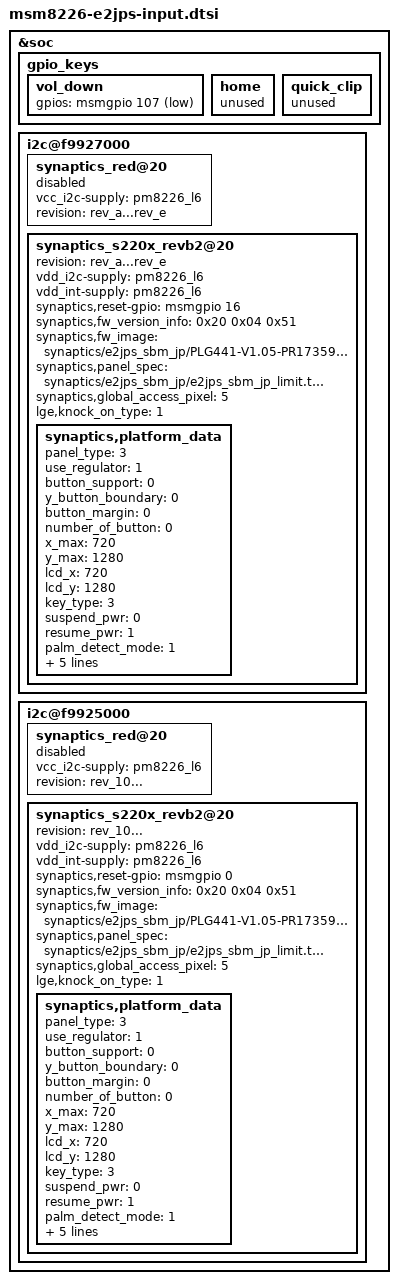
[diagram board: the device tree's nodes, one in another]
/* Copyright (c) 2013, LGE Electronics. All rights reserved.
 *
 * This program is free software; you can redistribute it and/or modify
 * it under the terms of the GNU General Public License version 2 and
 * only version 2 as published by the Free Software Foundation.
 *
 * This program is distributed in the hope that it will be useful,
 * but WITHOUT ANY WARRANTY; without even the implied warranty of
 * MERCHANTABILITY or FITNESS FOR A PARTICULAR PURPOSE.  See the
 * GNU General Public License for more details.
 */

&soc {
	gpio_keys {
		
		vol_down {
			gpios = <&msmgpio 107 0x1>;
		};
		
		home {
			unused;
		};

		quick_clip {
			unused;
		};
	};

	i2c@f9927000 { /* BLSP1 QUP5 */
		
		synaptics_red@20 {
			status = "disable";
			vcc_i2c-supply = <&pm8226_l6>;
			revision = "rev_a...rev_e";
		};
		
		synaptics_s220x_revb2@20 {
			status = "ok";
			revision = "rev_a...rev_e";
			vdd_i2c-supply = <&pm8226_l6>;
			vdd_int-supply = <&pm8226_l6>;
			synaptics,reset-gpio = <&msmgpio 16 0x00>;
			synaptics,fw_version_info = <0x20 0x04 0x51>;
			synaptics,fw_image = "synaptics/e2jps_sbm_jp/PLG441-V1.05-PR1735936-DS4.3.5.1.16_20045185.img";
			synaptics,panel_spec = "synaptics/e2jps_sbm_jp/e2jps_sbm_jp_limit.txt";
			synaptics,global_access_pixel = <5>;
			lge,knock_on_type = <1>;
			synaptics,platform_data	{
				/* firmware image depends on this value, temporarily used */
				/* 0: No image(default), 1: W3DS(TIM BR)(PLG312_T001), 2: W3S(VDF)(PLG311_T001), 3: X3(GLOBAL_COM, TRF_ATT, GLOBAL_SCA, KR)... */
				panel_type = <3>;
				use_regulator = <1>;
				button_support = <0>;
				y_button_boundary = <0>;
				button_margin = <0>;
				number_of_button = <0>;
				x_max = <720>;
				y_max = <1280>;
				lcd_x = <720>;
				lcd_y = <1280>;
				key_type = <3>;
				suspend_pwr = <0>;
				resume_pwr = <1>;
				palm_detect_mode = <1>;
				ghost_detection_enable = <0>;
				ghost_detection_button_enable = <0>;
				/* booting time, duration, jitter, finger diff, subtraction time, finger-subtraction-cnt, force-cont-mode,long press cnt, buttobtraction time, finger-subtraction-cnt, force-cont-mode,long press cnt, button duration, button int num, time after rebase */
				ghost_detection_value = <200 50 10 6 11 5 10 500 100 6 5>;
				vdd_voltage = <3050000>;
			};
		};

		
	};

	i2c@f9925000 { /* BLSP-1 QUP-3 */
		
		synaptics_red@20 {
			status = "disable";
			vcc_i2c-supply = <&pm8226_l6>;
			revision = "rev_10...";
		};
		
		synaptics_s220x_revb2@20 {
			status = "ok";
			revision = "rev_10...";
			vdd_i2c-supply = <&pm8226_l6>;
			vdd_int-supply = <&pm8226_l6>;
			synaptics,reset-gpio = <&msmgpio 0 0x00>;
			synaptics,fw_version_info = <0x20 0x04 0x51>;
			synaptics,fw_image = "synaptics/e2jps_sbm_jp/PLG441-V1.05-PR1735936-DS4.3.5.1.16_20045185.img";
			synaptics,panel_spec = "synaptics/e2jps_sbm_jp/e2jps_sbm_jp_limit.txt";
			synaptics,global_access_pixel = <5>;
			lge,knock_on_type = <1>;
			synaptics,platform_data	{
				/* firmware image depends on this value, temporarily used */
				/* 0: No image(default), 1: W3DS(TIM BR)(PLG312_T001), 2: W3S(VDF)(PLG311_T001), 3: X3(GLOBAL_COM, TRF_ATT, GLOBAL_SCA, KR)... */
				panel_type = <3>;
				use_regulator = <1>;
				button_support = <0>;
				y_button_boundary = <0>;
				button_margin = <0>;
				number_of_button = <0>;
				x_max = <720>;
				y_max = <1280>;
				lcd_x = <720>;
				lcd_y = <1280>;
				key_type = <3>;
				suspend_pwr = <0>;
				resume_pwr = <1>;
				palm_detect_mode = <1>;
				ghost_detection_enable = <0>;
				ghost_detection_button_enable = <0>;
				/* booting time, duration, jitter, finger diff, subtraction time, finger-subtraction-cnt, force-cont-mode,long press cnt, buttobtraction time, finger-subtraction-cnt, force-cont-mode,long press cnt, button duration, button int num, time after rebase */
				ghost_detection_value = <200 50 10 6 11 5 10 500 100 6 5>;
				vdd_voltage = <3050000>;
			};
		};

		
	};
	
	
	
};
